# STM32H533 register map
File version: 1.3
CPU: CM33 r0p0, little endian, MPU, FPU, 4 interrupt priority bits
Registers are 32-bit, read-write, reset 0x0 unless marked. A register's access mark holds for its fields unless they carry their own. Offsets are from the block's base; [hi:lo] are bit positions; 'fields as' and 'values as' point back to an identical list.

## UCPD — UCPD register block
Base 0x4000DC00
Same registers: UCPD_S 0x5000DC00
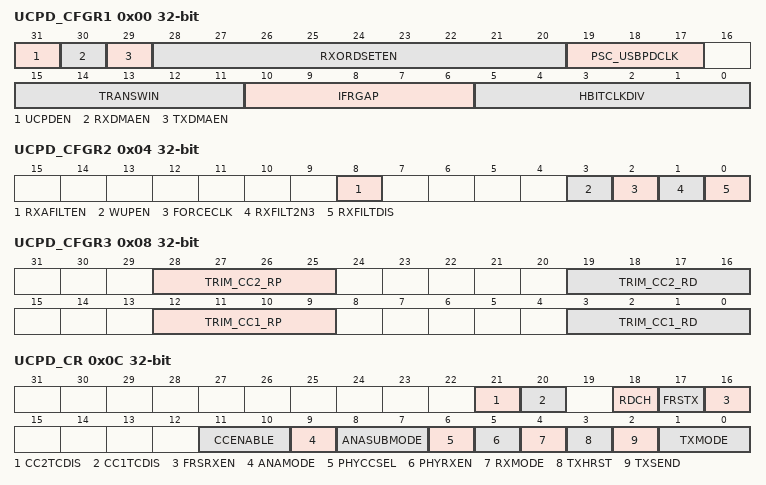
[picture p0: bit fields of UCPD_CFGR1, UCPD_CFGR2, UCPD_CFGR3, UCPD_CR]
0x00 UCPD_CFGR1 — UCPD configuration register 1
  [31] UCPDEN — UCPD peripheral enable
    0=Disable; 1=Enable
  [30] RXDMAEN — Reception DMA mode enable
    0=Disable; 1=Enable
  [29] TXDMAEN — Transmission DMA mode enable
    0=Disable; 1=Enable
  [28:20] RXORDSETEN — Receiver ordered set enable
  [19:17] PSC_USBPDCLK — Pre-scaler division ratio for generating ucpd_clk
    0=1 (bypass); 1=2; 2=4; 3=8; 4=16
  [15:11] TRANSWIN — Transition window duration
    0=Not supported; 1=2; 9=10 (recommended); 31=32
  [10:6] IFRGAP — Division ratio for producing inter-frame gap timer clock
    0=Not supported; 1=2; 13=14; 14=15; 15=16; 31=32
  [5:0] HBITCLKDIV — Division ratio for producing half-bit clock
    0=1 (bypass); 26=27; 63=64
0x04 UCPD_CFGR2 — UCPD configuration register 2
  [8] RXAFILTEN — Rx analog filter enable
    0=Disable; 1=Enable
  [3] WUPEN — Wake-up from Stop mode enable
    0=Disable; 1=Enable
  [2] FORCECLK — Force ClkReq clock request
    0=Do not force clock request; 1=Force clock request
  [1] RXFILT2N3 — BMC decoder Rx pre-filter sampling method
    0=3 samples; 1=2 samples
  [0] RXFILTDIS — BMC decoder Rx pre-filter enable
    0=Enable; 1=Disable
0x08 UCPD_CFGR3 — UCPD configuration register 3
  [28:25] TRIM_CC2_RP — SW trim value for Rp current sources on the CC2 line
  [19:16] TRIM_CC2_RD — SW trim value for Rd resistor on the CC2 line
  [12:9] TRIM_CC1_RP — SW trim value for Rp current sources on the CC1 line
  [3:0] TRIM_CC1_RD — SW trim value for Rd resistor on the CC1 line
0x0C UCPD_CR — UCPD control register
  [21] CC2TCDIS — CC2 Type-C detector disable
    0=Enable; 1=Disable
  [20] CC1TCDIS — CC1 Type-C detector disable
    0=Enable; 1=Disable
  [18] RDCH — Rdch condition drive
    0=No effect; 1=Rdch condition drive
  [17] FRSTX — FRS Tx signaling enable.
    0=No effect; 1=Enable
  [16] FRSRXEN — FRS event detection enable
    1=Enable
  [11:10] CCENABLE — CC line enable
    0=Disable both PHYs; 1=Enable CC1 PHY; 2=Enable CC2 PHY; 3=Enable CC1 and CC2 PHY
  [9] ANAMODE — Analog PHY operating mode
    0=Source; 1=Sink
  [8:7] ANASUBMODE — Analog PHY sub-mode
  [6] PHYCCSEL — CC1/CC2 line selector for USB Power Delivery signaling
    0=Use CC1 IO for Power Delivery communication; 1=Use CC2 IO for Power Delivery communication
  [5] PHYRXEN — USB Power Delivery receiver enable
    0=Disable; 1=Enable
  [4] RXMODE — Receiver mode
    0=Normal receive mode; 1=BIST receive mode (BIST test data mode)
  [3] TXHRST — Command to send a Tx Hard Reset
    0=No effect; 1=Start Tx Hard Reset message
  [2] TXSEND — Command to send a Tx packet
    0=No effect; 1=Start Tx packet transmission
  [1:0] TXMODE — Type of Tx packet
    0=Transmission of Tx packet previously defined in other registers; 1=Cable Reset sequence; 2=BIST test sequence (BIST Carrier Mode 2)
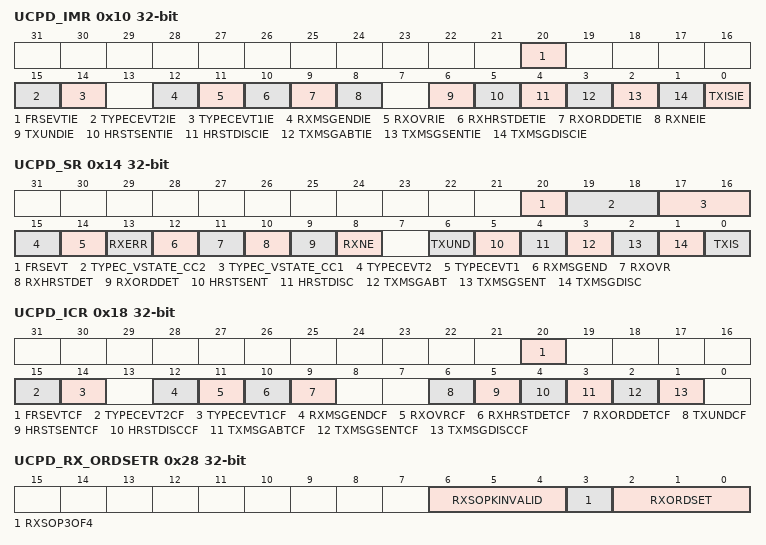
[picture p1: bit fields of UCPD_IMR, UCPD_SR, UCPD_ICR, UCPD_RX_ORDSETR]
0x10 UCPD_IMR — UCPD interrupt mask register
  [20] FRSEVTIE ro — FRSEVT interrupt enable
    0=Disable; 1=Enable
  [15] TYPECEVT2IE — TYPECEVT2 interrupt enable
    0=Disable; 1=Enable
  [14] TYPECEVT1IE — TYPECEVT1 interrupt enable
  [12] RXMSGENDIE — RXMSGEND interrupt enable
    0=Disable; 1=Enable
  [11] RXOVRIE — RXOVR interrupt enable
    0=Disable; 1=Enable
  [10] RXHRSTDETIE — RXHRSTDET interrupt enable
    0=Disable; 1=Enable
  [9] RXORDDETIE — RXORDDET interrupt enable
    0=Disable; 1=Enable
  [8] RXNEIE — RXNE interrupt enable
    0=Disable; 1=Enable
  [6] TXUNDIE — TXUND interrupt enable
    0=Disable; 1=Enable
  [5] HRSTSENTIE — HRSTSENT interrupt enable
    0=Disable; 1=Enable
  [4] HRSTDISCIE — HRSTDISC interrupt enable
    0=Disable; 1=Enable
  [3] TXMSGABTIE — TXMSGABT interrupt enable
    0=Disable; 1=Enable
  [2] TXMSGSENTIE — TXMSGSENT interrupt enable
    0=Disable; 1=Enable
  [1] TXMSGDISCIE — TXMSGDISC interrupt enable
    0=Disable; 1=Enable
  [0] TXISIE — TXIS interrupt enable
    0=Disable; 1=Enable
0x14 UCPD_SR ro — UCPD status register
  [20] FRSEVT — FRS detection event
    0=No new event; 1=New FRS receive event occurred
  [19:18] TYPEC_VSTATE_CC2 — CC2 line voltage level
    0=Lowest; 1=Low; 2=High; 3=Highest
  [17:16] TYPEC_VSTATE_CC1 — The status bitfield indicates the voltage level on the CC1 line in its steady state.
    0=Lowest; 1=Low; 2=High; 3=Highest
  [15] TYPECEVT2 — Type-C voltage level event on CC2 line
    0=No new event; 1=A new Type-C event
  [14] TYPECEVT1 — Type-C voltage level event on CC1 line
    0=No new event; 1=A new Type-C event
  [13] RXERR — Receive message error
    0=No error detected; 1=Error(s) detected
  [12] RXMSGEND — Rx message received
    0=No new Rx message received; 1=A new Rx message received
  [11] RXOVR — Rx data overflow detection
    0=No overflow; 1=Overflow
  [10] RXHRSTDET — Rx Hard Reset receipt detection
    0=Hard Reset not received; 1=Hard Reset received
  [9] RXORDDET — Rx ordered set (4 K-codes) detection
    0=No ordered set detected; 1=A new ordered set detected
  [8] RXNE — Receive data register not empty detection
    0=Rx data register empty; 1=Rx data register not empty
  [6] TXUND — Tx data underrun detection
    0=No Tx data underrun detected; 1=Tx data underrun detected
  [5] HRSTSENT — Hard Reset message sent
    0=No Hard Reset message sent; 1=Hard Reset message sent
  [4] HRSTDISC — Hard Reset discarded
    0=No Hard Reset discarded; 1=Hard Reset discarded
  [3] TXMSGABT — Transmit message abort
    0=No transmit message abort; 1=Transmit message abort
  [2] TXMSGSENT — Message transmission completed
    0=No Tx message completed; 1=Tx message completed
  [1] TXMSGDISC — Message transmission discarded
    0=No Tx message discarded; 1=Tx message discarded
  [0] TXIS — Transmit interrupt status
    0=New Tx data write not required; 1=New Tx data write required
0x18 UCPD_ICR wo — UCPD interrupt clear register
  [20] FRSEVTCF — FRS event flag (FRSEVT) clear
  [15] TYPECEVT2CF — Type-C CC2 line event flag (TYPECEVT2) clear
  [14] TYPECEVT1CF — Type-C CC1 event flag (TYPECEVT1) clear
  [12] RXMSGENDCF — Rx message received flag (RXMSGEND) clear
  [11] RXOVRCF — Rx overflow flag (RXOVR) clear
  [10] RXHRSTDETCF — Rx Hard Reset detect flag (RXHRSTDET) clear
  [9] RXORDDETCF — Rx ordered set detect flag (RXORDDET) clear
  [6] TXUNDCF — Tx underflow flag (TXUND) clear
  [5] HRSTSENTCF — Hard reset send flag (HRSTSENT) clear
  [4] HRSTDISCCF — Hard reset discard flag (HRSTDISC) clear
  [3] TXMSGABTCF — Tx message abort flag (TXMSGABT) clear
  [2] TXMSGSENTCF — Tx message send flag (TXMSGSENT) clear
  [1] TXMSGDISCCF — Tx message discard flag (TXMSGDISC) clear
0x1C UCPD_TX_ORDSETR — UCPD Tx ordered set type register
  [19:0] TXORDSET — Ordered set to transmit
0x20 UCPD_TX_PAYSZR — UCPD Tx payload size register
  [9:0] TXPAYSZ — Payload size yet to transmit
    2=2 bytes - the size of Control message from the protocol layer; 6=6 bytes - the shortest Data message allowed from the protocol layer); 30=30 bytes - the longest non-extended Data message allowed from the protocol layer; 0x106=262 bytes - the longest possible extended message; 0x3FF=1024 bytes - the longest possible payload (for future expansion)
0x24 UCPD_TXDR — UCPD Tx data register
  [7:0] TXDATA — Data byte to transmit
0x28 UCPD_RX_ORDSETR ro — UCPD Rx ordered set register
  [6:4] RXSOPKINVALID — The bitfield is for debug purposes only.
    0=No K-code corrupted; 1=First K-code corrupted; 2=Second K-code corrupted; 3=Third K-code corrupted; 4=Fourth K-code corrupted
  [3] RXSOP3OF4 — The bit indicates the number of correct K-codes.
    0=4 correct K-codes out of 4; 1=3 correct K-codes out of 4
  [2:0] RXORDSET — Rx ordered set code detected
    0=SOP code detected in receiver; 1=SOP' code detected in receiver; 2=SOP'' code detected in receiver; 3=SOP'_Debug detected in receiver; 4=SOP''_Debug detected in receiver; 5=Cable Reset detected in receiver; 6=SOP extension#1 detected in receiver; 7=SOP extension#2 detected in receiver
0x2C UCPD_RX_PAYSZR ro — UCPD Rx payload size register
  [9:0] RXPAYSZ — Rx payload size received
    values as UCPD_TX_PAYSZR.TXPAYSZ
0x30 UCPD_RXDR ro — UCPD receive data register
  [7:0] RXDATA — Data byte received
0x34 UCPD_RX_ORDEXTR1 — UCPD Rx ordered set extension register 1
  [19:0] RXSOPX1 — Ordered set 1 received
0x38 UCPD_RX_ORDEXTR2 — UCPD Rx ordered set extension register 2
  [19:0] RXSOPX2 — Ordered set 2 received
